AUTOSAR XML (schema 4-2-1)
package /MICROSAR/NvM_swc/DataTypes
  impl type NvM_RequestResultType: compu {0=NVM_REQ_OK, 1=NVM_REQ_NOT_OK, 2=NVM_REQ_PENDING, 3=NVM_REQ_INTEGRITY_FAILED, 4=NVM_REQ_BLOCK_SKIPPED, 5=NVM_REQ_NV_INVALIDATED, 6=NVM_REQ_CANCELED, 7=NVM_REQ_REDUNDANCY_FAILED, 8=NVM_REQ_RESTORED_FROM_ROM}, implementation-data-type=uint8
  impl type NvM_BlockIdType: range raw 1..32767, implementation-data-type=uint16
package /MICROSAR/NvM_swc/Interfaces
  client server interface NvMAdministration: is-service=true, service-kind=NON-VOLATILE-RAM-MANAGER
    operation SetBlockProtection: possible-error=NvMAdministration/E_NOT_OK
      arg ProtectionEnabled: type=boolean, direction=IN
    error E_NOT_OK: error-code=1
  client server interface NvMService_AC3_SRBS: is-service=true, service-kind=NON-VOLATILE-RAM-MANAGER
    6 x operation, all with possible-error=NvMService_AC3_SRBS/E_NOT_OK:
      GetErrorStatus
        arg ErrorStatus: type=NvM_RequestResultType, direction=OUT
      SetRamBlockStatus
        arg RamBlockStatus: type=boolean, direction=IN
      ReadBlock
        arg DstPtr: type=dtRef_VOID, direction=IN
      WriteBlock
        arg SrcPtr: type=dtRef_const_VOID, direction=IN
      InvalidateNvBlock
      EraseBlock
    error E_NOT_OK: error-code=1
package /MICROSAR/NvM_swc/ComponentTypes
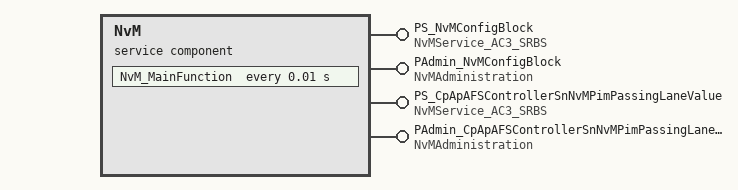
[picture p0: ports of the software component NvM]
  service sw component type NvM: category=SERVICE_COMPONENT
    4 x provide port:
      PS_NvMConfigBlock: provided-interface=NvMService_AC3_SRBS
      PAdmin_NvMConfigBlock: provided-interface=NvMAdministration
      PS_CpApAFSControllerSnNvMPimPassingLaneValue: provided-interface=NvMService_AC3_SRBS
      PAdmin_CpApAFSControllerSnNvMPimPassingLaneValue: provided-interface=NvMAdministration
    behavior NvMInternalBehavior: handle-termination-and-restart=NO-SUPPORT
      timing event Timer_NvM_MainFunction: start-on-event=NvM_MainFunction, period=0.01
      14 x operation invoked event:
        OpEventGetErrorStatus_GetErrorStatus_PS_NvMConfigBlock: start-on-event=GetErrorStatus, operation=PS_NvMConfigBlock.GetErrorStatus
        OpEventSetRamBlockStatus_SetRamBlockStatus_PS_NvMConfigBlock: start-on-event=SetRamBlockStatus, operation=PS_NvMConfigBlock.SetRamBlockStatus
        OpEventReadBlock_ReadBlock_PS_NvMConfigBlock: start-on-event=ReadBlock, operation=PS_NvMConfigBlock.ReadBlock
        OpEventWriteBlock_WriteBlock_PS_NvMConfigBlock: start-on-event=WriteBlock, operation=PS_NvMConfigBlock.WriteBlock
        OpEventInvalidateNvBlock_InvalidateNvBlock_PS_NvMConfigBlock: start-on-event=InvalidateNvBlock, operation=PS_NvMConfigBlock.InvalidateNvBlock
        OpEventEraseBlock_EraseBlock_PS_NvMConfigBlock: start-on-event=EraseBlock, operation=PS_NvMConfigBlock.EraseBlock
        OpEventSetBlockProtection_SetBlockProtection_PAdmin_NvMConfigBlock: start-on-event=SetBlockProtection, operation=PAdmin_NvMConfigBlock.SetBlockProtection
        OpEventGetErrorStatus_GetErrorStatus_PS_CpApAFSControllerSnNvMPimPassingLaneValue: start-on-event=GetErrorStatus, operation=PS_CpApAFSControllerSnNvMPimPassingLaneValue.GetErrorStatus
        OpEventSetRamBlockStatus_SetRamBlockStatus_PS_CpApAFSControllerSnNvMPimPassingLaneValue: start-on-event=SetRamBlockStatus, operation=PS_CpApAFSControllerSnNvMPimPassingLaneValue.SetRamBlockStatus
        OpEventReadBlock_ReadBlock_PS_CpApAFSControllerSnNvMPimPassingLaneValue: start-on-event=ReadBlock, operation=PS_CpApAFSControllerSnNvMPimPassingLaneValue.ReadBlock
        OpEventWriteBlock_WriteBlock_PS_CpApAFSControllerSnNvMPimPassingLaneValue: start-on-event=WriteBlock, operation=PS_CpApAFSControllerSnNvMPimPassingLaneValue.WriteBlock
        OpEventInvalidateNvBlock_InvalidateNvBlock_PS_CpApAFSControllerSnNvMPimPassingLaneValue: start-on-event=InvalidateNvBlock, operation=PS_CpApAFSControllerSnNvMPimPassingLaneValue.InvalidateNvBlock
        OpEventEraseBlock_EraseBlock_PS_CpApAFSControllerSnNvMPimPassingLaneValue: start-on-event=EraseBlock, operation=PS_CpApAFSControllerSnNvMPimPassingLaneValue.EraseBlock
        OpEventSetBlockProtection_SetBlockProtection_PAdmin_CpApAFSControllerSnNvMPimPassingLaneValue: start-on-event=SetBlockProtection, operation=PAdmin_CpApAFSControllerSnNvMPimPassingLaneValue.SetBlockProtection
      port-api-options:
        {enable-take-address=true, indirect-api=false, port-defined-argument-value{value=1, value-type=NvM_BlockIdType}, port=PS_NvMConfigBlock}
        {enable-take-address=true, indirect-api=false, port-defined-argument-value{value=1, value-type=NvM_BlockIdType}, port=PAdmin_NvMConfigBlock}
        {enable-take-address=true, indirect-api=false, port-defined-argument-value{value=3, value-type=NvM_BlockIdType}, port=PS_CpApAFSControllerSnNvMPimPassingLaneValue}
        {enable-take-address=true, indirect-api=false, port-defined-argument-value{value=3, value-type=NvM_BlockIdType}, port=PAdmin_CpApAFSControllerSnNvMPimPassingLaneValue}
      8 x runnable:
        NvM_MainFunction
        GetErrorStatus: can-be-invoked-concurrently=true, symbol=NvM_GetErrorStatus
        SetRamBlockStatus: can-be-invoked-concurrently=true, symbol=NvM_SetRamBlockStatus
        ReadBlock: can-be-invoked-concurrently=true, symbol=NvM_ReadBlock
        WriteBlock: can-be-invoked-concurrently=true, symbol=NvM_WriteBlock
        InvalidateNvBlock: can-be-invoked-concurrently=true, symbol=NvM_InvalidateNvBlock
        EraseBlock: can-be-invoked-concurrently=true, symbol=NvM_EraseNvBlock
        SetBlockProtection: can-be-invoked-concurrently=true, symbol=NvM_SetBlockProtection
  swc implementation NvMImplementation: programming-language=C, behavior=NvMInternalBehavior
